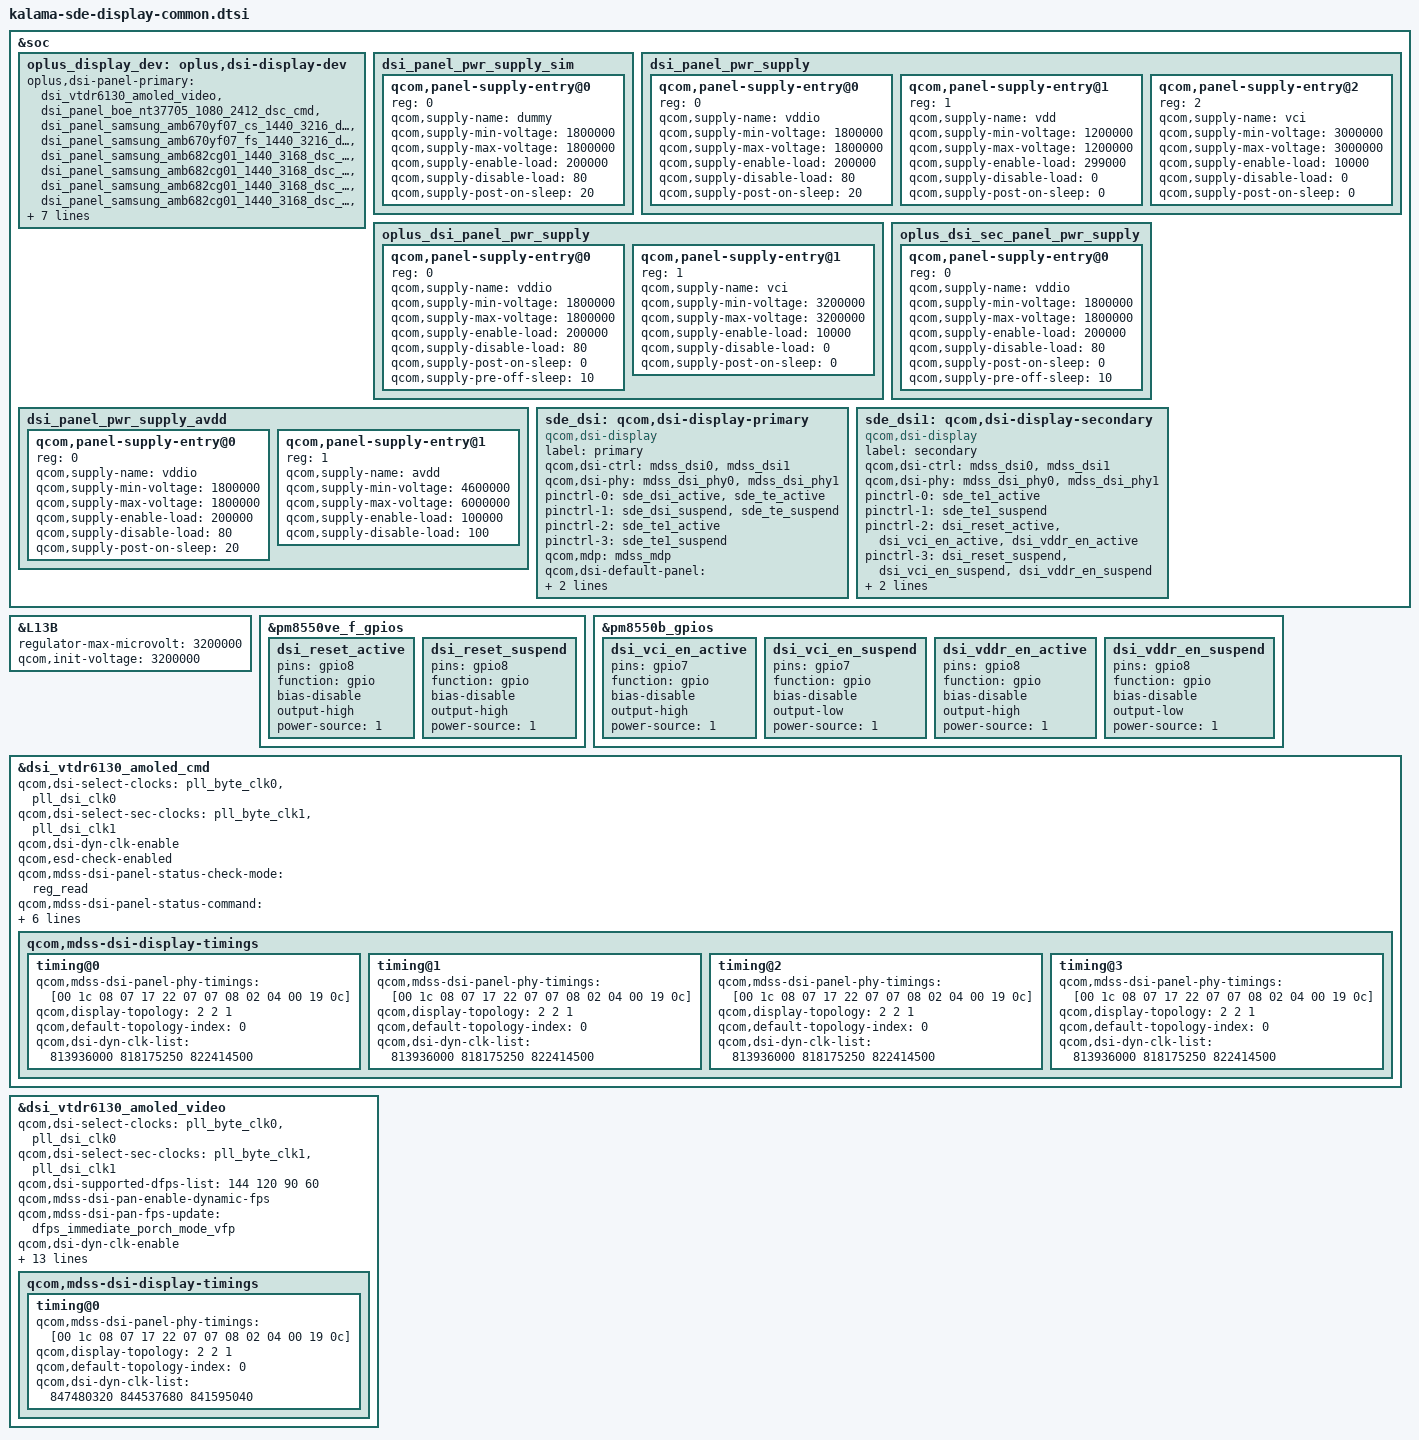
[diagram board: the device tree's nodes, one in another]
#include "dsi-panel-vtdr6130-dsc-fhd-plus-cmd.dtsi"
#include "dsi-panel-vtdr6130-dsc-fhd-plus-video.dtsi"

#include "kalama-sde-display-pinctrl.dtsi"

//#ifdef OPLUS_FEATURE_DISPLAY
#include "dsi-panel-boe-nt37705-1080-2412-dsc-cmd.dtsi"
#include "dsi-panel-samsung-amb670yf07-cs-1440-3216-dsc-cmd.dtsi"
#include "dsi-panel-samsung-amb670yf07-fs-1440-3216-dsc-cmd.dtsi"
#include "dsi-panel-samsung-amb682cg01-1440-3168-dsc-cmd.dtsi"
#include "dsi-panel-samsung-amb682cg01-1440-3168-dsc-cmd-dvt.dtsi"
#include "dsi-panel-samsung-amb682cg01-1440-3168-dsc-cmd-ldo.dtsi"
#include "dsi-panel-samsung-amb682cg01-1440-3168-dsc-cmd-evt2.dtsi"
#include "dsi-panel-samsung-amb682cg01-1440-3168-dsc-cmd-evt1.dtsi"
#include "dsi-panel-samsung-amb682cg01-1440-3168-dsc-cmd-t0.dtsi"
#include "dsi-panel-boe-nt37705-1116-2484-dsc-cmd.dtsi"
#include "dsi-panel-boe-nt37900-2440-2268-dsc-cmd.dtsi"

&soc {
	oplus_display_dev: oplus,dsi-display-dev {
		oplus,dsi-panel-primary = <
			&dsi_vtdr6130_amoled_video
			&dsi_panel_boe_nt37705_1080_2412_dsc_cmd
			&dsi_panel_samsung_amb670yf07_cs_1440_3216_dsc_cmd
			&dsi_panel_samsung_amb670yf07_fs_1440_3216_dsc_cmd
			&dsi_panel_samsung_amb682cg01_1440_3168_dsc_cmd
			&dsi_panel_samsung_amb682cg01_1440_3168_dsc_cmd_dvt
			&dsi_panel_samsung_amb682cg01_1440_3168_dsc_cmd_ldo
			&dsi_panel_samsung_amb682cg01_1440_3168_dsc_cmd_evt2
			&dsi_panel_samsung_amb682cg01_1440_3168_dsc_cmd_evt1
			&dsi_panel_samsung_amb682cg01_1440_3168_dsc_cmd_t0
			&dsi_panel_boe_nt37900_2440_2268_dsc_cmd
		>;
		oplus,dsi-panel-secondary = <
			&dsi_panel_boe_nt37705_1116_2484_dsc_cmd
			&dsi_vtdr6130_amoled_video
		>;
		oplus,dsi-panel-extended = <>;
	};
};

&L13B {
	regulator-max-microvolt = <3200000>;
	qcom,init-voltage = <3200000>;
};

&pm8550ve_f_gpios{
	dsi_reset_active: dsi_reset_active {
		pins = "gpio8";
		function = "gpio";
		bias-disable; /* NO PULL */
		output-high;
		power-source = <1>; /* 1.8V */
	};

	dsi_reset_suspend: dsi_reset_suspend {
		pins = "gpio8";
		function = "gpio";
		bias-disable; /* NO PULL */
		output-high;
		power-source = <1>; /* 1.8V */
	};
};

&pm8550b_gpios{
	dsi_vci_en_active: dsi_vci_en_active {
		pins = "gpio7";
		function = "gpio";
		bias-disable; /* NO PULL */
		output-high;
		power-source = <1>; /* 1.8V */
	};

	dsi_vci_en_suspend: dsi_vci_en_suspend {
		pins = "gpio7";
		function = "gpio";
		bias-disable; /* NO PULL */
		output-low;
		power-source = <1>; /* 1.8V */
	};

	dsi_vddr_en_active: dsi_vddr_en_active {
		pins = "gpio8";
		function = "gpio";
		bias-disable; /* NO PULL */
		output-high;
		power-source = <1>; /* 1.8V */
	};

	dsi_vddr_en_suspend: dsi_vddr_en_suspend {
		pins = "gpio8";
		function = "gpio";
		bias-disable; /* NO PULL */
		output-low;
		power-source = <1>; /* 1.8V */
	};
};
//#endif /* OPLUS_FEATURE_DISPLAY */

&soc {
	dsi_panel_pwr_supply_sim: dsi_panel_pwr_supply_sim {
		#address-cells = <1>;
		#size-cells = <0>;

		qcom,panel-supply-entry@0 {
			reg = <0>;
			qcom,supply-name = "dummy";
			qcom,supply-min-voltage = <1800000>;
			qcom,supply-max-voltage = <1800000>;
			qcom,supply-enable-load = <200000>;
			qcom,supply-disable-load = <80>;
			qcom,supply-post-on-sleep = <20>;
		};
	};

	dsi_panel_pwr_supply: dsi_panel_pwr_supply {
		#address-cells = <1>;
		#size-cells = <0>;

		qcom,panel-supply-entry@0 {
			reg = <0>;
			qcom,supply-name = "vddio";
			qcom,supply-min-voltage = <1800000>;
			qcom,supply-max-voltage = <1800000>;
			qcom,supply-enable-load = <200000>;
			qcom,supply-disable-load = <80>;
			qcom,supply-post-on-sleep = <20>;
		};

		qcom,panel-supply-entry@1 {
			reg = <1>;
			qcom,supply-name = "vdd";
			qcom,supply-min-voltage = <1200000>;
			qcom,supply-max-voltage = <1200000>;
			qcom,supply-enable-load = <299000>;
			qcom,supply-disable-load = <0>;
			qcom,supply-post-on-sleep = <0>;
		};

		qcom,panel-supply-entry@2 {
			reg = <2>;
			qcom,supply-name = "vci";
			qcom,supply-min-voltage = <3000000>;
			qcom,supply-max-voltage = <3000000>;
			qcom,supply-enable-load = <10000>;
			qcom,supply-disable-load = <0>;
			qcom,supply-post-on-sleep = <0>;
		};
	};

//#ifdef OPLUS_FEATURE_DISPLAY
	oplus_dsi_panel_pwr_supply: oplus_dsi_panel_pwr_supply {
		#address-cells = <1>;
		#size-cells = <0>;

		qcom,panel-supply-entry@0 {
			reg = <0>;
			qcom,supply-name = "vddio";
			qcom,supply-min-voltage = <1800000>;
			qcom,supply-max-voltage = <1800000>;
			qcom,supply-enable-load = <200000>;
			qcom,supply-disable-load = <80>;
			qcom,supply-post-on-sleep = <0>;
			qcom,supply-pre-off-sleep = <10>;
		};

		qcom,panel-supply-entry@1 {
			reg = <1>;
			qcom,supply-name = "vci";
			qcom,supply-min-voltage = <3200000>;
			qcom,supply-max-voltage = <3200000>;
			qcom,supply-enable-load = <10000>;
			qcom,supply-disable-load = <0>;
			qcom,supply-post-on-sleep = <0>;
		};
	};
	oplus_dsi_sec_panel_pwr_supply: oplus_dsi_sec_panel_pwr_supply {
		#address-cells = <1>;
		#size-cells = <0>;

		qcom,panel-supply-entry@0 {
			reg = <0>;
			qcom,supply-name = "vddio";
			qcom,supply-min-voltage = <1800000>;
			qcom,supply-max-voltage = <1800000>;
			qcom,supply-enable-load = <200000>;
			qcom,supply-disable-load = <80>;
			qcom,supply-post-on-sleep = <0>;
			qcom,supply-pre-off-sleep = <10>;
		};
	};
//#endif /* OPLUS_FEATURE_DISPLAY */

	dsi_panel_pwr_supply_avdd: dsi_panel_pwr_supply_avdd {
		#address-cells = <1>;
		#size-cells = <0>;

		qcom,panel-supply-entry@0 {
			reg = <0>;
			qcom,supply-name = "vddio";
			qcom,supply-min-voltage = <1800000>;
			qcom,supply-max-voltage = <1800000>;
			qcom,supply-enable-load = <200000>;
			qcom,supply-disable-load = <80>;
			qcom,supply-post-on-sleep = <20>;
		};

		qcom,panel-supply-entry@1 {
			reg = <1>;
			qcom,supply-name = "avdd";
			qcom,supply-min-voltage = <4600000>;
			qcom,supply-max-voltage = <6000000>;
			qcom,supply-enable-load = <100000>;
			qcom,supply-disable-load = <100>;
		};
	};

	sde_dsi: qcom,dsi-display-primary {
		compatible = "qcom,dsi-display";
		label = "primary";

		qcom,dsi-ctrl = <&mdss_dsi0 &mdss_dsi1>;
		qcom,dsi-phy = <&mdss_dsi_phy0 &mdss_dsi_phy1>;

//#ifdef OPLUS_FEATURE_DISPLAY
		pinctrl-names = "panel_active", "panel_suspend",
				"te1_active", "te1_suspend";
		pinctrl-0 = <&sde_dsi_active &sde_te_active>;
		pinctrl-1 = <&sde_dsi_suspend &sde_te_suspend>;
		pinctrl-2 = <&sde_te1_active>;
		pinctrl-3 = <&sde_te1_suspend>;
//#else /* OPLUS_FEATURE_DISPLAY */
//		pinctrl-names = "panel_active", "panel_suspend";
//		pinctrl-0 = <&sde_dsi_active &sde_te_active>;
//		pinctrl-1 = <&sde_dsi_suspend &sde_te_suspend>;

//		qcom,platform-te-gpio = <&tlmm 86 0>;
//		qcom,panel-te-source = <0>;
//#endif /* OPLUS_FEATURE_DISPLAY */

		qcom,mdp = <&mdss_mdp>;
		qcom,dsi-default-panel = <&dsi_vtdr6130_amoled_cmd>;
		qcom,demura-panel-id = <0x0122e700 0x00000471>;
	};

	sde_dsi1: qcom,dsi-display-secondary {
		compatible = "qcom,dsi-display";
		label = "secondary";

		qcom,dsi-ctrl = <&mdss_dsi0 &mdss_dsi1>;
		qcom,dsi-phy = <&mdss_dsi_phy0 &mdss_dsi_phy1>;

//#ifdef OPLUS_FEATURE_DISPLAY
		pinctrl-names = "panel_active", "panel_suspend",
				"oplus_panel_active", "oplus_panel_suspend";
		pinctrl-0 = <&sde_te1_active>;
		pinctrl-1 = <&sde_te1_suspend>;
		pinctrl-2 = <&dsi_reset_active &dsi_vci_en_active &dsi_vddr_en_active>;
		pinctrl-3 = <&dsi_reset_suspend &dsi_vci_en_suspend &dsi_vddr_en_suspend>;
//#else /* OPLUS_FEATURE_DISPLAY */
//		pinctrl-names = "panel_active", "panel_suspend";
//		pinctrl-0 = <&sde_dsi1_active &sde_te1_active>;
//		pinctrl-1 = <&sde_dsi1_suspend &sde_te1_suspend>;

//		qcom,platform-te-gpio = <&tlmm 87 0>;
//		qcom,panel-te-source = <1>;
//#endif /* OPLUS_FEATURE_DISPLAY */

		qcom,mdp = <&mdss_mdp>;
		qcom,demura-panel-id = <0x0 0x0>;
	};
};

/* PHY TIMINGS REVISION YL with reduced margins */
&dsi_vtdr6130_amoled_cmd {
	qcom,dsi-select-clocks = "pll_byte_clk0", "pll_dsi_clk0";
	qcom,dsi-select-sec-clocks = "pll_byte_clk1", "pll_dsi_clk1";

	qcom,dsi-dyn-clk-enable;

	qcom,esd-check-enabled;
	qcom,mdss-dsi-panel-status-check-mode = "reg_read";
	qcom,mdss-dsi-panel-status-command = [06 01 00 01 00 00 01 0a];
	qcom,mdss-dsi-panel-status-command-state = "dsi_lp_mode";
	qcom,mdss-dsi-panel-status-value = <0x9c>;
	qcom,mdss-dsi-panel-status-read-length = <1>;

	qcom,mdss-dsi-panel-hdr-enabled;

	qcom,mdss-dsi-display-timings {
		timing@0 {
			qcom,mdss-dsi-panel-phy-timings = [00 1c 08 07 17 22 07
				07 08 02 04 00 19 0c];
			qcom,display-topology = <2 2 1>;
			qcom,default-topology-index = <0>;
			qcom,dsi-dyn-clk-list = <813936000 818175250 822414500>;
		};
		timing@1 {
			qcom,mdss-dsi-panel-phy-timings = [00 1c 08 07 17 22 07
				07 08 02 04 00 19 0c];
			qcom,display-topology = <2 2 1>;
			qcom,default-topology-index = <0>;
			qcom,dsi-dyn-clk-list = <813936000 818175250 822414500>;
		};
		timing@2 {
			qcom,mdss-dsi-panel-phy-timings = [00 1c 08 07 17 22 07
				07 08 02 04 00 19 0c];
			qcom,display-topology = <2 2 1>;
			qcom,default-topology-index = <0>;
			qcom,dsi-dyn-clk-list = <813936000 818175250 822414500>;
		};
		timing@3 {
			qcom,mdss-dsi-panel-phy-timings = [00 1c 08 07 17 22 07
				07 08 02 04 00 19 0c];
			qcom,display-topology = <2 2 1>;
			qcom,default-topology-index = <0>;
			qcom,dsi-dyn-clk-list = <813936000 818175250 822414500>;
		};
	};
};

&dsi_vtdr6130_amoled_video {
	qcom,dsi-select-clocks = "pll_byte_clk0", "pll_dsi_clk0";
	qcom,dsi-select-sec-clocks = "pll_byte_clk1", "pll_dsi_clk1";
	qcom,dsi-supported-dfps-list = <144 120 90 60>;
	qcom,mdss-dsi-pan-enable-dynamic-fps;
	qcom,mdss-dsi-pan-fps-update = "dfps_immediate_porch_mode_vfp";

	qcom,dsi-dyn-clk-enable;
	qcom,dsi-dyn-clk-type = "constant-fps-adjust-hfp";

	qcom,qsync-enable;
	qcom,dsi-supported-qsync-min-fps-list = <80 70 60 50>;

//#ifdef OPLUS_FEATURE_DISPLAY
//	qcom,esd-check-enabled;
//#endif /* OPLUS_FEATURE_DISPLAY */
	qcom,mdss-dsi-panel-status-check-mode = "reg_read";
	qcom,mdss-dsi-panel-status-command = [06 01 00 01 00 00 01 0a];
	qcom,mdss-dsi-panel-status-command-state = "dsi_lp_mode";
	qcom,mdss-dsi-panel-status-value = <0x9c>;
	qcom,mdss-dsi-panel-status-read-length = <1>;

	qcom,mdss-dsi-panel-hdr-enabled;

	qcom,mdss-dsi-display-timings {
		timing@0 {
			qcom,mdss-dsi-panel-phy-timings = [00 1c 08 07 17 22 07
				07 08 02 04 00 19 0c];
			qcom,display-topology = <2 2 1>;
			qcom,default-topology-index = <0>;
			qcom,dsi-dyn-clk-list = <847480320 844537680 841595040>;
		};
	};
};
